# CY8C5868AXI_LP035 register map
File version: 0.1
Registers are 8-bit, read-write, no defined reset value unless marked. A register's access mark holds for its fields unless they carry their own. Offsets are from the block's base; [hi:lo] are bit positions.

## Tag — UART
Base 0x00000000
0x40006424 RX_Tag_RX_ADDRESS1 — RX Address1 Register
0x40006434 RX_Tag_RX_ADDRESS2 — RX Address2 Register
0x40006444 RX_Tag_RX_DATA — RX Data Register
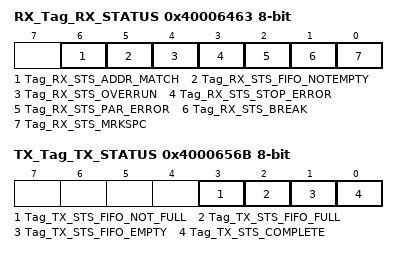
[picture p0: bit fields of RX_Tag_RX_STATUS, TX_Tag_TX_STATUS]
0x40006463 RX_Tag_RX_STATUS — RX status register
  [6] Tag_RX_STS_ADDR_MATCH ro, [5] Tag_RX_STS_FIFO_NOTEMPTY ro, [4] Tag_RX_STS_OVERRUN ro, [3] Tag_RX_STS_STOP_ERROR ro, [2] Tag_RX_STS_PAR_ERROR ro, [1] Tag_RX_STS_BREAK ro, [0] Tag_RX_STS_MRKSPC ro
0x40006544 TX_Tag_TX_DATA — TX Data Register
0x4000656B TX_Tag_TX_STATUS — TX status register
  [3] Tag_TX_STS_FIFO_NOT_FULL ro, [2] Tag_TX_STS_FIFO_FULL ro, [1] Tag_TX_STS_FIFO_EMPTY ro, [0] Tag_TX_STS_COMPLETE ro

## Beagle — UART
Base 0x00000000
0x40006422 RX_Beagle_RX_ADDRESS1 — RX Address1 Register
0x40006432 RX_Beagle_RX_ADDRESS2 — RX Address2 Register
0x40006442 RX_Beagle_RX_DATA — RX Data Register
0x4000644B TX_Beagle_TX_DATA — TX Data Register
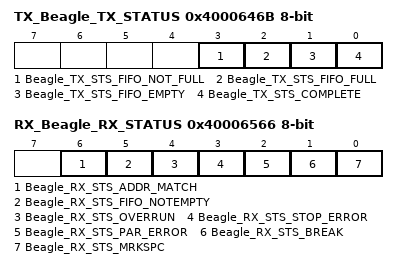
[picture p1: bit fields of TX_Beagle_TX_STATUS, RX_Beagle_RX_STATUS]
0x4000646B TX_Beagle_TX_STATUS — TX status register
  [3] Beagle_TX_STS_FIFO_NOT_FULL ro, [2] Beagle_TX_STS_FIFO_FULL ro, [1] Beagle_TX_STS_FIFO_EMPTY ro, [0] Beagle_TX_STS_COMPLETE ro
0x40006566 RX_Beagle_RX_STATUS — RX status register
  [6] Beagle_RX_STS_ADDR_MATCH ro, [5] Beagle_RX_STS_FIFO_NOTEMPTY ro, [4] Beagle_RX_STS_OVERRUN ro, [3] Beagle_RX_STS_STOP_ERROR ro, [2] Beagle_RX_STS_PAR_ERROR ro, [1] Beagle_RX_STS_BREAK ro, [0] Beagle_RX_STS_MRKSPC ro

## LCD2 — UART
Base 0x00000000
0x4000644D TX_LCD2_TX_DATA — TX Data Register
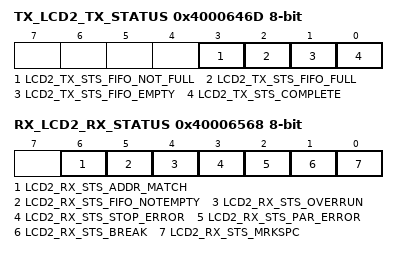
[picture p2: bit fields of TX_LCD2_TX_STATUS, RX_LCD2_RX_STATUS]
0x4000646D TX_LCD2_TX_STATUS — TX status register
  [3] LCD2_TX_STS_FIFO_NOT_FULL ro, [2] LCD2_TX_STS_FIFO_FULL ro, [1] LCD2_TX_STS_FIFO_EMPTY ro, [0] LCD2_TX_STS_COMPLETE ro
0x4000652B RX_LCD2_RX_ADDRESS1 — RX Address1 Register
0x4000653B RX_LCD2_RX_ADDRESS2 — RX Address2 Register
0x4000654B RX_LCD2_RX_DATA — RX Data Register
0x40006568 RX_LCD2_RX_STATUS — RX status register
  [6] LCD2_RX_STS_ADDR_MATCH ro, [5] LCD2_RX_STS_FIFO_NOTEMPTY ro, [4] LCD2_RX_STS_OVERRUN ro, [3] LCD2_RX_STS_STOP_ERROR ro, [2] LCD2_RX_STS_PAR_ERROR ro, [1] LCD2_RX_STS_BREAK ro, [0] LCD2_RX_STS_MRKSPC ro

## Pump_AL — UART
Base 0x00000000
0x40006526 RX_Pump_AL_RX_ADDRESS1 — RX Address1 Register
0x40006536 RX_Pump_AL_RX_ADDRESS2 — RX Address2 Register
0x40006546 RX_Pump_AL_RX_DATA — RX Data Register
0x4000654A TX_Pump_AL_TX_DATA — TX Data Register
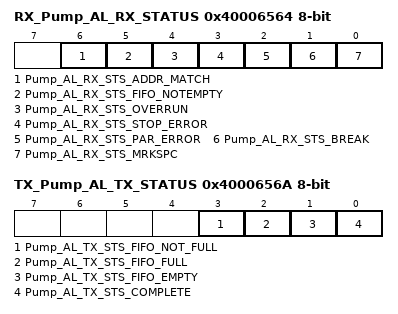
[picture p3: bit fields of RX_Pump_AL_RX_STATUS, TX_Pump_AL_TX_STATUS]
0x40006564 RX_Pump_AL_RX_STATUS — RX status register
  [6] Pump_AL_RX_STS_ADDR_MATCH ro, [5] Pump_AL_RX_STS_FIFO_NOTEMPTY ro, [4] Pump_AL_RX_STS_OVERRUN ro, [3] Pump_AL_RX_STS_STOP_ERROR ro, [2] Pump_AL_RX_STS_PAR_ERROR ro, [1] Pump_AL_RX_STS_BREAK ro, [0] Pump_AL_RX_STS_MRKSPC ro
0x4000656A TX_Pump_AL_TX_STATUS — TX status register
  [3] Pump_AL_TX_STS_FIFO_NOT_FULL ro, [2] Pump_AL_TX_STS_FIFO_FULL ro, [1] Pump_AL_TX_STS_FIFO_EMPTY ro, [0] Pump_AL_TX_STS_COMPLETE ro

## Code_Bar — UART
Base 0x00000000
0x40006427 RX_Code_Bar_RX_ADDRESS1 — RX Address1 Register
0x40006437 RX_Code_Bar_RX_ADDRESS2 — RX Address2 Register
0x40006447 RX_Code_Bar_RX_DATA — RX Data Register
0x40006449 TX_Code_Bar_TX_DATA — TX Data Register
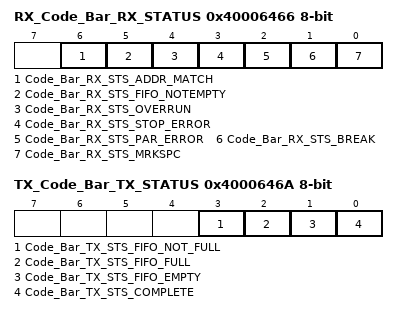
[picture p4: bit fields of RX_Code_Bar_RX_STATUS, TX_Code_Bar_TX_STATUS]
0x40006466 RX_Code_Bar_RX_STATUS — RX status register
  [6] Code_Bar_RX_STS_ADDR_MATCH ro, [5] Code_Bar_RX_STS_FIFO_NOTEMPTY ro, [4] Code_Bar_RX_STS_OVERRUN ro, [3] Code_Bar_RX_STS_STOP_ERROR ro, [2] Code_Bar_RX_STS_PAR_ERROR ro, [1] Code_Bar_RX_STS_BREAK ro, [0] Code_Bar_RX_STS_MRKSPC ro
0x4000646A TX_Code_Bar_TX_STATUS — TX status register
  [3] Code_Bar_TX_STS_FIFO_NOT_FULL ro, [2] Code_Bar_TX_STS_FIFO_FULL ro, [1] Code_Bar_TX_STS_FIFO_EMPTY ro, [0] Code_Bar_TX_STS_COMPLETE ro

## LCD1 — UART
Base 0x00000000
0x40006425 RX_LCD1_RX_ADDRESS1 — RX Address1 Register
0x40006435 RX_LCD1_RX_ADDRESS2 — RX Address2 Register
0x40006445 RX_LCD1_RX_DATA — RX Data Register
0x4000644C TX_LCD1_TX_DATA — TX Data Register
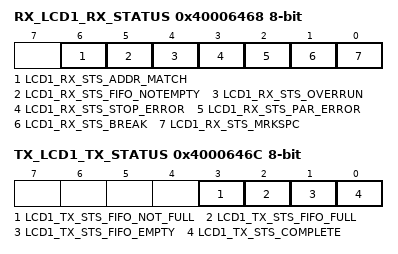
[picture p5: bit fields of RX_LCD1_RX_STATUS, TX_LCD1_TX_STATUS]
0x40006468 RX_LCD1_RX_STATUS — RX status register
  [6] LCD1_RX_STS_ADDR_MATCH ro, [5] LCD1_RX_STS_FIFO_NOTEMPTY ro, [4] LCD1_RX_STS_OVERRUN ro, [3] LCD1_RX_STS_STOP_ERROR ro, [2] LCD1_RX_STS_PAR_ERROR ro, [1] LCD1_RX_STS_BREAK ro, [0] LCD1_RX_STS_MRKSPC ro
0x4000646C TX_LCD1_TX_STATUS — TX status register
  [3] LCD1_TX_STS_FIFO_NOT_FULL ro, [2] LCD1_TX_STS_FIFO_FULL ro, [1] LCD1_TX_STS_FIFO_EMPTY ro, [0] LCD1_TX_STS_COMPLETE ro
